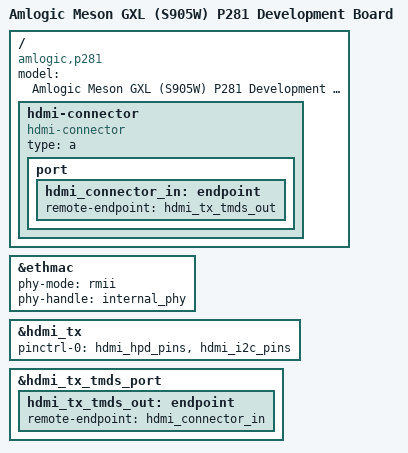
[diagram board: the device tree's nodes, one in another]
/*
 * Copyright (c) 2018 Martin Blumenstingl <martin.blumenstingl@googlemail.com>.
 * Based on meson-gxl-s905d-p231.dts:
 * - Copyright (c) 2016 Endless Computers, Inc.
 *   Author: Carlo Caione <carlo@endlessm.com>
 *
 * SPDX-License-Identifier: (GPL-2.0+ OR MIT)
 */

/dts-v1/;

#include "meson-gxl-s905w.dtsi"
#include "meson-gx-p23x-q20x.dtsi"

/ {
	compatible = "amlogic,p281", "amlogic,s905w", "amlogic,meson-gxl";
	model = "Amlogic Meson GXL (S905W) P281 Development Board";

	hdmi-connector {
		compatible = "hdmi-connector";
		type = "a";

		port {
			hdmi_connector_in: endpoint {
				remote-endpoint = <&hdmi_tx_tmds_out>;
			};
		};
	};
};

/* P281 has only internal PHY port */
&ethmac {
	phy-mode = "rmii";
	phy-handle = <&internal_phy>;
};

&hdmi_tx {
	status = "okay";
	pinctrl-0 = <&hdmi_hpd_pins>, <&hdmi_i2c_pins>;
	pinctrl-names = "default";
};

&hdmi_tx_tmds_port {
	hdmi_tx_tmds_out: endpoint {
		remote-endpoint = <&hdmi_connector_in>;
	};
};
